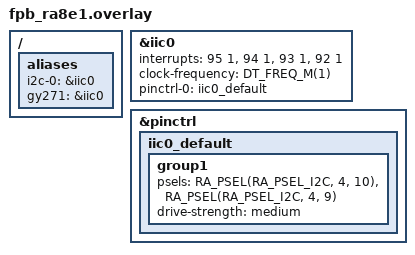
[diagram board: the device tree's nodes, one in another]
/*
 * Copyright (c) 2026 Renesas Electronics Corporation
 *
 * SPDX-License-Identifier: Apache-2.0
 */

/ {
	aliases {
		i2c-0 = &iic0;
		gy271 = &iic0;
	};
};

&iic0 {
	interrupts = <95 1>, <94 1>, <93 1>, <92 1>;
	interrupt-names = "rxi", "txi", "tei", "eri";
	status = "okay";
	#address-cells = <1>;
	#size-cells = <0>;
	clock-frequency = <DT_FREQ_M(1)>;
	pinctrl-0 = <&iic0_default>;
	pinctrl-names = "default";
};

&pinctrl {
	iic0_default: iic0_default {
		group1 {
			/* SCL1 SDA1*/
			psels = <RA_PSEL(RA_PSEL_I2C, 4, 10)>,
				<RA_PSEL(RA_PSEL_I2C, 4, 9)>;
			drive-strength = "medium";
		};
	};
};
